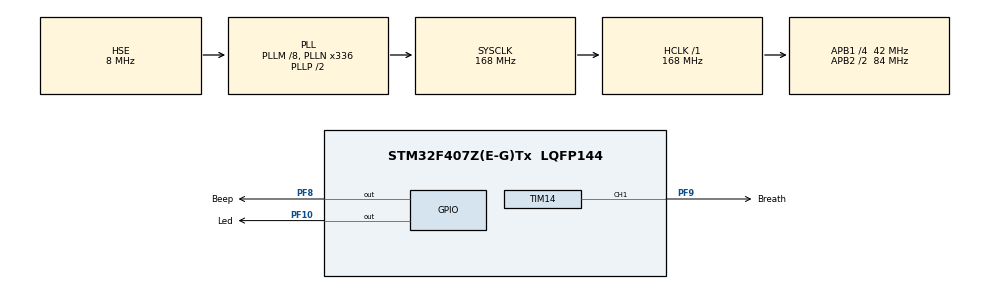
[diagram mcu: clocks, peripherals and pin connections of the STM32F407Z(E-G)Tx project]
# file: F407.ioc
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Mcu.Family=STM32F4
Mcu.Name=STM32F407Z(E-G)Tx
Mcu.Package=LQFP144
NVIC.PriorityGroup=NVIC_PRIORITYGROUP_2
NVIC.TIM8_TRG_COM_TIM14_IRQn=true\:2\:2\:true\:false\:true\:true\:false
PA13.Mode=Serial_Wire
PA13.Signal=SYS_JTMS-SWDIO
PA14.Mode=Serial_Wire
PA14.Signal=SYS_JTCK-SWCLK
PC14-OSC32_IN.Mode=LSE-External-Oscillator
PC14-OSC32_IN.Signal=RCC_OSC32_IN
PC15-OSC32_OUT.Mode=LSE-External-Oscillator
PC15-OSC32_OUT.Signal=RCC_OSC32_OUT
PD5.Signal=FSMC_NWE
PF10.GPIO_Label=Led
PF10.GPIO_PuPd=GPIO_PULLUP
PF10.GPIO_Speed=GPIO_SPEED_FREQ_MEDIUM
PF10.PinState=GPIO_PIN_RESET
PF10.Signal=GPIO_Output
PF8.GPIO_Label=Beep
PF8.PinState=GPIO_PIN_RESET
PF8.Signal=GPIO_Output
PF9.GPIO_Label=Breath
PF9.Signal=S_TIM14_CH1
PH0-OSC_IN.Mode=HSE-External-Clock-Source
PH0-OSC_IN.Signal=RCC_OSC_IN
PH1-OSC_OUT.Mode=HSE-External-Clock-Source
PH1-OSC_OUT.Signal=RCC_OSC_OUT
ProjectManager.HeapSize=0x200
ProjectManager.StackSize=0x400
ProjectManager.TargetToolchain=MDK-ARM V5.27
RCC.48MHZClocksFreq_Value=84000000
RCC.AHBFreq_Value=168000000
RCC.APB1CLKDivider=RCC_HCLK_DIV4
RCC.APB1Freq_Value=42000000
RCC.APB1TimFreq_Value=84000000
RCC.APB2CLKDivider=RCC_HCLK_DIV2
RCC.APB2Freq_Value=84000000
RCC.APB2TimFreq_Value=168000000
RCC.CortexFreq_Value=168000000
RCC.HCLKFreq_Value=168000000
RCC.HSE_VALUE=8000000
RCC.HSI_VALUE=16000000
RCC.LockedElements=APB1Output,TimPrescOut
RCC.PLLM=8
RCC.PLLN=336
RCC.PLLSourceVirtual=RCC_PLLSOURCE_HSE
RCC.SYSCLKFreq_VALUE=168000000
RCC.SYSCLKSource=RCC_SYSCLKSOURCE_PLLCLK
RCC.VCOOutputFreq_Value=336000000
SH.FSMC_NWE.0=FSMC_NWE
SH.S_TIM14_CH1.0=TIM14_CH1,PWM Generation1 CH1
TIM14.AutoReloadPreload=TIM_AUTORELOAD_PRELOAD_ENABLE
TIM14.Channel=TIM_CHANNEL_1
TIM14.OCFastMode_PWM=TIM_OCFAST_ENABLE
TIM14.OCPolarity_1=TIM_OCPOLARITY_LOW
TIM14.Period=500
TIM14.Prescaler=84
TIM14.Pulse=250
VP_TIM14_VS_ClockSourceINT.Mode=Enable_Timer
board=custom

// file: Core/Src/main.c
/* USER CODE BEGIN Header */
/**
  ******************************************************************************
  * @file           : main.c
  * @brief          : Main program body
  ******************************************************************************
  * @attention
  *
  * <h2><center>&copy; Copyright (c) 2021 STMicroelectronics.
  * All rights reserved.</center></h2>
  *
  * This software component is licensed by ST under BSD 3-Clause license,
  * the "License"; You may not use this file except in compliance with the
  * License. You may obtain a copy of the License at:
  *                        opensource.org/licenses/BSD-3-Clause
  *
  ******************************************************************************
  */
/* USER CODE END Header */
#include "main.h"

TIM_HandleTypeDef htim14;

/* USER CODE END PV */

void SystemClock_Config(void);
static void MX_GPIO_Init(void);
static void MX_TIM14_Init(void);

int main(void)
{

  /* MCU Configuration--------------------------------------------------------*/

  /* Reset of all peripherals, Initializes the Flash interface and the Systick. */
  HAL_Init();

  /* Configure the system clock */
  SystemClock_Config();

  /* Initialize all configured peripherals */
  MX_GPIO_Init();
  MX_TIM14_Init();

  /* Infinite loop */
  /* USER CODE BEGIN WHILE */
	HAL_TIM_PWM_Start(&htim14,TIM_CHANNEL_1);
  //printf("Hello");
  while (1)
  {
    /* USER CODE END WHILE */

  }
}

void SystemClock_Config(void)
{
  RCC_OscInitTypeDef RCC_OscInitStruct = {0};
  RCC_ClkInitTypeDef RCC_ClkInitStruct = {0};

  /** Configure the main internal regulator output voltage
  */
  __HAL_RCC_PWR_CLK_ENABLE();
  __HAL_PWR_VOLTAGESCALING_CONFIG(PWR_REGULATOR_VOLTAGE_SCALE1);
  /** Initializes the RCC Oscillators according to the specified parameters
  * in the RCC_OscInitTypeDef structure.
  */
  RCC_OscInitStruct.OscillatorType = RCC_OSCILLATORTYPE_HSE;
  RCC_OscInitStruct.HSEState = RCC_HSE_BYPASS;
  RCC_OscInitStruct.PLL.PLLState = RCC_PLL_ON;
  RCC_OscInitStruct.PLL.PLLSource = RCC_PLLSOURCE_HSE;
  RCC_OscInitStruct.PLL.PLLM = 8;
  RCC_OscInitStruct.PLL.PLLN = 336;
  RCC_OscInitStruct.PLL.PLLP = RCC_PLLP_DIV2;
  RCC_OscInitStruct.PLL.PLLQ = 4;
  if (HAL_RCC_OscConfig(&RCC_OscInitStruct) != HAL_OK)
  {
    Error_Handler();
  }
  /** Initializes the CPU, AHB and APB buses clocks
  */
  RCC_ClkInitStruct.ClockType = RCC_CLOCKTYPE_HCLK|RCC_CLOCKTYPE_SYSCLK
                              |RCC_CLOCKTYPE_PCLK1|RCC_CLOCKTYPE_PCLK2;
  RCC_ClkInitStruct.SYSCLKSource = RCC_SYSCLKSOURCE_PLLCLK;
  RCC_ClkInitStruct.AHBCLKDivider = RCC_SYSCLK_DIV1;
  RCC_ClkInitStruct.APB1CLKDivider = RCC_HCLK_DIV4;
  RCC_ClkInitStruct.APB2CLKDivider = RCC_HCLK_DIV2;

  if (HAL_RCC_ClockConfig(&RCC_ClkInitStruct, FLASH_LATENCY_5) != HAL_OK)
  {
    Error_Handler();
  }
}

static void MX_TIM14_Init(void)
{

  TIM_OC_InitTypeDef sConfigOC = {0};

  htim14.Instance = TIM14;
  htim14.Init.Prescaler = 84;
  htim14.Init.CounterMode = TIM_COUNTERMODE_UP;
  htim14.Init.Period = 500;
  htim14.Init.ClockDivision = TIM_CLOCKDIVISION_DIV1;
  htim14.Init.AutoReloadPreload = TIM_AUTORELOAD_PRELOAD_ENABLE;
  if (HAL_TIM_Base_Init(&htim14) != HAL_OK)
  {
    Error_Handler();
  }
  if (HAL_TIM_PWM_Init(&htim14) != HAL_OK)
  {
    Error_Handler();
  }
  sConfigOC.OCMode = TIM_OCMODE_PWM1;
  sConfigOC.Pulse = 250;
  sConfigOC.OCPolarity = TIM_OCPOLARITY_LOW;
  sConfigOC.OCFastMode = TIM_OCFAST_ENABLE;
  if (HAL_TIM_PWM_ConfigChannel(&htim14, &sConfigOC, TIM_CHANNEL_1) != HAL_OK)
  {
    Error_Handler();
  }
  HAL_TIM_MspPostInit(&htim14);

}

static void MX_GPIO_Init(void)
{
  GPIO_InitTypeDef GPIO_InitStruct = {0};

  /* GPIO Ports Clock Enable */
  __HAL_RCC_GPIOC_CLK_ENABLE();
  __HAL_RCC_GPIOF_CLK_ENABLE();
  __HAL_RCC_GPIOH_CLK_ENABLE();
  __HAL_RCC_GPIOA_CLK_ENABLE();
  __HAL_RCC_GPIOD_CLK_ENABLE();

  /*Configure GPIO pin Output Level */
  HAL_GPIO_WritePin(GPIOF, Beep_Pin|Led_Pin, GPIO_PIN_RESET);

  /*Configure GPIO pin : Beep_Pin */
  GPIO_InitStruct.Pin = Beep_Pin;
  GPIO_InitStruct.Mode = GPIO_MODE_OUTPUT_PP;
  GPIO_InitStruct.Pull = GPIO_NOPULL;
  GPIO_InitStruct.Speed = GPIO_SPEED_FREQ_LOW;
  HAL_GPIO_Init(Beep_GPIO_Port, &GPIO_InitStruct);

  /*Configure GPIO pin : Led_Pin */
  GPIO_InitStruct.Pin = Led_Pin;
  GPIO_InitStruct.Mode = GPIO_MODE_OUTPUT_PP;
  GPIO_InitStruct.Pull = GPIO_PULLUP;
  GPIO_InitStruct.Speed = GPIO_SPEED_FREQ_MEDIUM;
  HAL_GPIO_Init(Led_GPIO_Port, &GPIO_InitStruct);

  /*Configure GPIO pin : PD5 */
  GPIO_InitStruct.Pin = GPIO_PIN_5;
  GPIO_InitStruct.Mode = GPIO_MODE_AF_PP;
  GPIO_InitStruct.Pull = GPIO_NOPULL;
  GPIO_InitStruct.Speed = GPIO_SPEED_FREQ_VERY_HIGH;
  GPIO_InitStruct.Alternate = GPIO_AF12_FSMC;
  HAL_GPIO_Init(GPIOD, &GPIO_InitStruct);

}

void Error_Handler(void)
{
}

/************************ (C) COPYRIGHT STMicroelectronics *****END OF FILE****/
